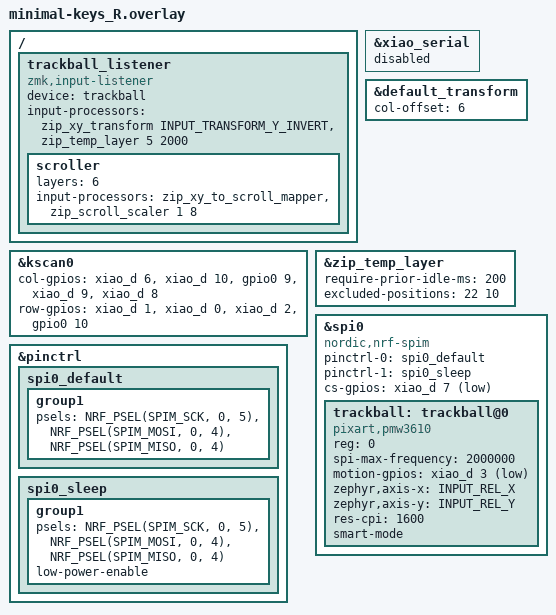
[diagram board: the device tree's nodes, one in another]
#include "minimal-keys.dtsi"
#include <zephyr/dt-bindings/input/input-event-codes.h>
#include <dt-bindings/zmk/input_transform.h>
#include <input/processors.dtsi>

&xiao_serial { status = "disabled"; };

&default_transform {
    col-offset = <6>;
};

&kscan0 {
    col-gpios
        = <&xiao_d 6 GPIO_ACTIVE_HIGH>   // Col0: P1.11_D6_TX
        , <&xiao_d 10 GPIO_ACTIVE_HIGH>  // Col1: P1.15_D10_MOSI
        , <&gpio0 9 GPIO_ACTIVE_HIGH>    // Col2: P0.09 (NFC1)
        , <&xiao_d 9 GPIO_ACTIVE_HIGH>   // Col3: P1.14_D9_MISO
        , <&xiao_d 8 GPIO_ACTIVE_HIGH>   // Col4: P1.13_D8_SCK
        ;
    row-gpios
        = <&xiao_d 1 (GPIO_ACTIVE_HIGH | GPIO_PULL_DOWN)>  // Row0
        , <&xiao_d 0 (GPIO_ACTIVE_HIGH | GPIO_PULL_DOWN)>  // Row1
        , <&xiao_d 2 (GPIO_ACTIVE_HIGH | GPIO_PULL_DOWN)>  // Row2
        , <&gpio0 10 (GPIO_ACTIVE_HIGH | GPIO_PULL_DOWN)>  // Row3
        ;
};

&pinctrl {
    spi0_default: spi0_default {
        group1 {
            psels = <NRF_PSEL(SPIM_SCK, 0, 5)>,
                <NRF_PSEL(SPIM_MOSI, 0, 4)>,
                <NRF_PSEL(SPIM_MISO, 0, 4)>;
        };
    };

    spi0_sleep: spi0_sleep {
        group1 {
            psels = <NRF_PSEL(SPIM_SCK, 0, 5)>,
                <NRF_PSEL(SPIM_MOSI, 0, 4)>,
                <NRF_PSEL(SPIM_MISO, 0, 4)>;
            low-power-enable;
        };
    };
};

// AML 防誤觸：打字 200ms 內不觸發，MB1/MB2 不退出 MOUSE 層
&zip_temp_layer {
    require-prior-idle-ms = <200>;
    excluded-positions = <22 10>;  // MB1, MB2（左半 inner column）
};

/ {
    trackball_listener {
        compatible = "zmk,input-listener";
        device = <&trackball>;

        // 軸向校正 + 自動滑鼠層
        input-processors =
            <&zip_xy_transform INPUT_TRANSFORM_Y_INVERT>,
            <&zip_temp_layer 5 2000>;

        // 捲動模式：SCROLL 層（Layer 6）啟用時軌跡球變捲輪
        scroller {
            layers = <6>;
            input-processors =
                <&zip_xy_to_scroll_mapper>,
                <&zip_scroll_scaler 1 8>;
        };
    };
};

&spi0 {
    status = "okay";
    compatible = "nordic,nrf-spim";
    pinctrl-0 = <&spi0_default>;
    pinctrl-1 = <&spi0_sleep>;
    pinctrl-names = "default", "sleep";
    cs-gpios = <&xiao_d 7 GPIO_ACTIVE_LOW>;

    trackball: trackball@0 {
        status = "okay";
        compatible = "pixart,pmw3610";
        reg = <0>;
        spi-max-frequency = <2000000>;
        motion-gpios = <&xiao_d 3 (GPIO_ACTIVE_LOW | GPIO_PULL_UP)>;
        zephyr,axis-x = <INPUT_REL_X>;
        zephyr,axis-y = <INPUT_REL_Y>;
        res-cpi = <1600>;
        smart-mode;
    };
};
